VERSION "b"

NS_ :

BS_:

BU_:

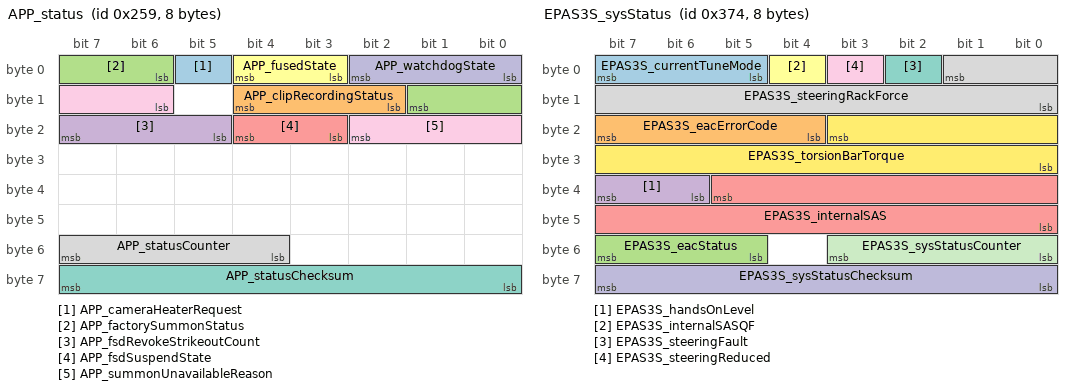
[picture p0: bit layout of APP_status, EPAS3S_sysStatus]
BO_ 601 APP_status: 8 ETH
 SG_ APP_cameraHeaterRequest : 5|1@1+ (1,0) [0|1] "" ETH
 SG_ APP_clipRecordingStatus : 10|3@1+ (1,0) [0|7] "" ETH
 SG_ APP_factorySummonStatus : 6|4@1+ (1,0) [0|15] "" ETH
 SG_ APP_fsdRevokeStrikeoutCount : 21|3@1+ (1,0) [0|7] "" ETH
 SG_ APP_fsdSuspendState : 19|2@1+ (1,0) [0|3] "" ETH
 SG_ APP_fusedState : 3|2@1+ (1,0) [0|3] "" ETH
 SG_ APP_statusChecksum : 56|8@1+ (1,0) [0|255] "" ETH
 SG_ APP_statusCounter : 52|4@1+ (1,0) [0|15] "" ETH
 SG_ APP_summonUnavailableReason : 14|5@1+ (1,0) [0|31] "" ETH
 SG_ APP_watchdogState : 0|3@1+ (1,0) [0|7] "" ETH

BO_ 884 EPAS3S_sysStatus: 8 ETH
 SG_ EPAS3S_currentTuneMode : 5|3@1+ (1,0) [0|7] "" ETH
 SG_ EPAS3S_eacErrorCode : 20|4@1+ (1,0) [0|15] "" ETH
 SG_ EPAS3S_eacStatus : 53|3@1+ (1,0) [0|7] "" ETH
 SG_ EPAS3S_handsOnLevel : 38|2@1+ (1,0) [0|3] "" ETH
 SG_ EPAS3S_internalSAS : 37|14@0+ (0.1,-819.2) [-819.2|819.1] "deg" ETH
 SG_ EPAS3S_internalSASQF : 4|1@1+ (1,0) [0|1] "" ETH
 SG_ EPAS3S_steeringFault : 2|1@1+ (1,0) [0|1] "" ETH
 SG_ EPAS3S_steeringRackForce : 1|10@0+ (50,-25575) [-25575|25575] "N" ETH
 SG_ EPAS3S_steeringReduced : 3|1@1+ (1,0) [0|1] "" ETH
 SG_ EPAS3S_sysStatusChecksum : 56|8@1+ (1,0) [0|255] "" ETH
 SG_ EPAS3S_sysStatusCounter : 48|4@1+ (1,0) [0|15] "" ETH
 SG_ EPAS3S_torsionBarTorque : 19|12@0+ (0.01,-20.5) [-20.5|20.45] "Nm" ETH

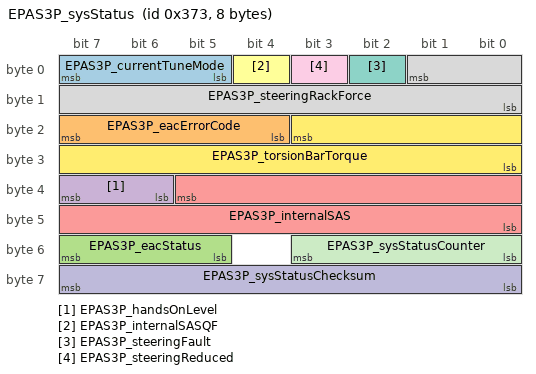
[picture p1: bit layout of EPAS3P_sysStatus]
BO_ 883 EPAS3P_sysStatus: 8 ETH
 SG_ EPAS3P_currentTuneMode : 5|3@1+ (1,0) [0|7] "" ETH
 SG_ EPAS3P_eacErrorCode : 20|4@1+ (1,0) [0|15] "" ETH
 SG_ EPAS3P_eacStatus : 53|3@1+ (1,0) [0|7] "" ETH
 SG_ EPAS3P_handsOnLevel : 38|2@1+ (1,0) [0|3] "" ETH
 SG_ EPAS3P_internalSAS : 37|14@0+ (0.1,-819.2) [-819.2|819.1] "deg" ETH
 SG_ EPAS3P_internalSASQF : 4|1@1+ (1,0) [0|1] "" ETH
 SG_ EPAS3P_steeringFault : 2|1@1+ (1,0) [0|1] "" ETH
 SG_ EPAS3P_steeringRackForce : 1|10@0+ (50,-25575) [-25575|25575] "N" ETH
 SG_ EPAS3P_steeringReduced : 3|1@1+ (1,0) [0|1] "" ETH
 SG_ EPAS3P_sysStatusChecksum : 56|8@1+ (1,0) [0|255] "" ETH
 SG_ EPAS3P_sysStatusCounter : 48|4@1+ (1,0) [0|15] "" ETH
 SG_ EPAS3P_torsionBarTorque : 19|12@0+ (0.01,-20.5) [-20.5|20.45] "Nm" ETH

BO_ 921 DAS_status: 8 ETH
 SG_ DAS_autoLaneChangeState : 46|5@1+ (1,0) [0|31] "" ETH
 SG_ DAS_autoParked : 25|1@1+ (1,0) [0|1] "" ETH
 SG_ DAS_autoparkReady : 24|1@1+ (1,0) [0|1] "" ETH
 SG_ DAS_autoparkWaitingForBrake : 26|1@1+ (1,0) [0|1] "" ETH
 SG_ DAS_autopilotHandsOnState : 42|4@1+ (1,0) [0|15] "" ETH
 SG_ DAS_autopilotState : 0|4@1+ (1,0) [0|15] "" ETH
 SG_ DAS_blindSpotRearLeft : 4|2@1+ (1,0) [0|3] "" ETH
 SG_ DAS_blindSpotRearRight : 6|2@1+ (1,0) [0|3] "" ETH
 SG_ DAS_fleetSpeedState : 40|2@1+ (1,0) [0|3] "" ETH
 SG_ DAS_forwardCollisionWarning : 22|2@1+ (1,0) [0|3] "" ETH
 SG_ DAS_fusedSpeedLimit : 8|5@1+ (5,0) [0|155] "kph/mph" ETH
 SG_ DAS_heaterState : 21|1@1+ (1,0) [0|1] "" ETH
 SG_ DAS_laneDepartureWarning : 37|3@1+ (1,0) [0|7] "" ETH
 SG_ DAS_lssState : 29|3@1+ (1,0) [0|7] "" ETH
 SG_ DAS_sideCollisionAvoid : 32|2@1+ (1,0) [0|3] "" ETH
 SG_ DAS_sideCollisionInhibit : 36|1@1+ (1,0) [0|1] "" ETH
 SG_ DAS_sideCollisionWarning : 34|2@1+ (1,0) [0|3] "" ETH
 SG_ DAS_statusChecksum : 56|8@1+ (1,0) [0|255] "" ETH
 SG_ DAS_statusCounter : 52|4@1+ (1,0) [0|15] "" ETH
 SG_ DAS_summonAvailable : 51|1@1+ (1,0) [0|1] "" ETH
 SG_ DAS_summonClearedGate : 15|1@1+ (1,0) [0|1] "" ETH
 SG_ DAS_summonFwdLeashReached : 27|1@1+ (1,0) [0|1] "" ETH
 SG_ DAS_summonObstacle : 14|1@1+ (1,0) [0|1] "" ETH
 SG_ DAS_summonRvsLeashReached : 28|1@1+ (1,0) [0|1] "" ETH
 SG_ DAS_suppressSpeedWarning : 13|1@1+ (1,0) [0|1] "" ETH
 SG_ DAS_visionOnlySpeedLimit : 16|5@1+ (5,0) [0|155] "kph/mph" ETH

BO_ 1021 UI_autopilotControl: 8 ETH
 SG_ UI_autopilotControlIndex M : 0|3@1+ (1,0) [0|7] "" ETH
 SG_ UI_hovEnabled m0 : 3|1@1+ (1,0) [0|1] "" ETH
 SG_ UI_donDisableAutoWiperDuration m0 : 4|3@1+ (1,0) [0|7] "" ETH
 SG_ UI_donDisableOnAutoWiperSpeed m0 : 7|4@1+ (1,0) [0|15] "" ETH
 SG_ UI_blindspotMinSpeed m0 : 11|4@1+ (1,0) [0|15] "" ETH
 SG_ UI_blindspotDistance m0 : 15|3@1+ (1,0) [0|7] "" ETH
 SG_ UI_blindspotTTC m0 : 18|3@1+ (1,0) [0|7] "" ETH
 SG_ UI_donStopEndOfRampBuffer m0 : 21|3@1+ (1,0) [0|7] "" ETH
 SG_ UI_donDisableCutin m0 : 24|1@1+ (1,0) [0|1] "" ETH
 SG_ UI_smartSetSpeedOffset m0 : 25|6@1+ (1,-30) [-30|33] "%" ETH
 SG_ UI_smartSetSpeedOffsetType m0 : 31|1@1+ (1,0) [0|1] "" ETH
 SG_ UI_fsdVisualizationEnabled m0 : 37|1@1+ (1,0) [0|1] "" ETH
 SG_ UI_fsdStopsControlEnabled m0 : 38|1@1+ (1,0) [0|1] "" ETH
 SG_ UI_fsdContinueOnGreenWithCIPV m0 : 39|1@1+ (1,0) [0|1] "" ETH
 SG_ UI_smartSetSpeed m0 : 40|1@1+ (1,0) [0|1] "" ETH
 SG_ UI_homelinkNearby m0 : 45|1@1+ (1,0) [0|1] "" ETH
 SG_ UI_enableFullSelfDriving m0 : 46|1@1+ (1,0) [0|1] "" ETH
 SG_ UI_hasFullSelfDriving m0 : 47|1@1+ (1,0) [0|1] "" ETH
 SG_ UI_autosteerActivation m0 : 48|1@1+ (1,0) [0|1] "" ETH
 SG_ UI_autopilotDrivingProfile m0 : 49|2@1+ (1,0) [0|3] "" ETH
 SG_ UI_fsdBetaRequest m0 : 51|1@1+ (1,0) [0|1] "" ETH
 SG_ UI_fullSelfDrivingSuspended m0 : 52|1@1+ (1,0) [0|1] "" ETH
 SG_ UI_autopilotControlMux0Valid m0 : 63|1@1+ (1,0) [0|1] "" ETH
 SG_ UI_driverMonitorConfirmation m1 : 17|1@1+ (1,0) [0|1] "" ETH
 SG_ UI_applyEceR79 m1 : 19|1@1+ (1,0) [0|1] "" ETH
 SG_ UI_enableMapStops m1 : 20|1@1+ (1,0) [0|1] "" ETH
 SG_ UI_disableMain m1 : 23|1@1+ (1,0) [0|1] "" ETH
 SG_ UI_disableNarrow m1 : 24|1@1+ (1,0) [0|1] "" ETH
 SG_ UI_disableFisheye m1 : 25|1@1+ (1,0) [0|1] "" ETH
 SG_ UI_disableLeftPillar m1 : 26|1@1+ (1,0) [0|1] "" ETH
 SG_ UI_disableRightPillar m1 : 27|1@1+ (1,0) [0|1] "" ETH
 SG_ UI_disableLeftRepeater m1 : 28|1@1+ (1,0) [0|1] "" ETH
 SG_ UI_disableRightRepeater m1 : 29|1@1+ (1,0) [0|1] "" ETH
 SG_ UI_disableBackup m1 : 30|1@1+ (1,0) [0|1] "" ETH
 SG_ UI_disableRadar m1 : 31|1@1+ (1,0) [0|1] "" ETH
 SG_ UI_noStalkConfirmAlertHaptic m1 : 32|1@1+ (1,0) [0|1] "" ETH
 SG_ UI_ulcSnooze m1 : 36|1@1+ (1,0) [0|1] "" ETH
 SG_ UI_noStalkConfirmAlertChime m1 : 37|1@1+ (1,0) [0|1] "" ETH
 SG_ UI_factorySummonEnable m1 : 39|1@1+ (1,0) [0|1] "" ETH
 SG_ UI_apmv3Branch m1 : 40|3@1+ (1,0) [0|7] "" ETH
 SG_ UI_enableCabinCamera m1 : 43|1@1+ (1,0) [0|1] "" ETH
 SG_ UI_enableAutopilotStopWarning m1 : 44|1@1+ (1,0) [0|1] "" ETH
 SG_ UI_showLaneGraph m1 : 45|1@1+ (1,0) [0|1] "" ETH
 SG_ UI_showTrackLabels m1 : 46|1@1+ (1,0) [0|1] "" ETH
 SG_ UI_hardCoreSummon m1 : 47|1@1+ (1,0) [0|1] "" ETH
 SG_ UI_enableCabinCameraTelemetry m1 : 48|1@1+ (1,0) [0|1] "" ETH
 SG_ UI_enableVisionSpeedControl m1 : 49|1@1+ (1,0) [0|1] "" ETH
 SG_ UI_autopilotTelemetryInChina m1 : 50|1@1+ (1,0) [0|1] "" ETH
 SG_ UI_enableTeslaAutopark m1 : 51|1@1+ (1,0) [0|1] "" ETH
 SG_ UI_autoTurnSignalMode m1 : 52|1@1+ (1,0) [0|1] "" ETH
 SG_ UI_enableCautionLightControl m1 : 54|1@1+ (1,0) [0|1] "" ETH
 SG_ UI_autopilotControlMux1Valid m1 : 63|1@1+ (1,0) [0|1] "" ETH

VAL_ 601 APP_clipRecordingStatus 0 "NO_DRIVE" 1 "IDLE" 2 "RECORDING" 3 "TRIGGERED" 4 "FAULTED" ;
VAL_ 601 APP_factorySummonStatus 0 "SNA" 1 "ACTIVE" 2 "AVAILABLE" 3 "UNAVAILABLE_NO_QR_INSTRUCTION" 4 "UNAVAILABLE_GOAL_TOO_FAR" 5 "UNAVAILABLE_NO_GPS" 6 "UNAVAILABLE_VEHICLE_SPEED_INVALID" 7 "UNAVAILABLE_HEADING_NOT_INITIALIZED" 8 "END_OF_ROUTE" ;
VAL_ 601 APP_fsdRevokeStrikeoutCount 7 "SNA" ;
VAL_ 601 APP_fsdSuspendState 0 "NOT_SUSPENDED" 1 "SUSPENDED" 3 "SNA" ;
VAL_ 601 APP_fusedState 0 "UNKNOWN" 1 "UNFUSED" 2 "FUSED" 3 "SNA" ;
VAL_ 601 APP_summonUnavailableReason 0 "UNKNOWN" 1 "NONE" 2 "NOT_IN_PARK" 3 "CAMERA_STREAM" 4 "CAMERA_BLOCKED" 5 "ULTRASONIC_BLOCKED" 6 "ULTRASONIC_FAULT" 7 "CRUISE_UNAVAILABLE" 8 "EAC_UNAVAILABLE" 9 "PUBLIC_ROAD" 10 "POOR_CONNECTION" 11 "PHONE_GPS_UNAVAILABLE" 12 "EGO_GPS_UNAVAILABLE" 13 "PHONE_IS_TOO_FAR" 14 "END_OF_LEASH" 15 "CAMERA_NOT_CALIBRATED" 16 "VISION_HEALTH_CRITICAL" 17 "ULTRASONIC_STALE" 18 "ALL_SENSORS_OCCLUDED" 19 "PUBLIC_ROAD_BOUNDARIES_NOT_VALID" 20 "NO_CONTEXT" ;
VAL_ 601 APP_watchdogState 0 "UNKNOWN" 1 "DEGRADED" 2 "CRITICAL" 3 "HEALTHY" 7 "SNA" ;
VAL_ 884 EPAS3S_currentTuneMode 0 "DM_COMFORT" 1 "DM_STANDARD" 2 "DM_SPORT" 3 "RWD_COMFORT" 4 "RWD_STANDARD" 5 "RWD_SPORT" ;
VAL_ 884 EPAS3S_eacErrorCode 0 "EAC_ERROR_IDLE" 1 "EAC_ERROR_MIN_SPEED" 2 "EAC_ERROR_MAX_SPEED" 3 "EAC_ERROR_HANDS_ON" 4 "EAC_ERROR_TMP_FAULT" 5 "EAR_ERROR_MAX_STEER_DELTA" 6 "EAC_ERROR_HIGH_ANGLE_REQ" 7 "EAC_ERROR_HIGH_ANGLE_RATE_REQ" 8 "EAC_ERROR_HIGH_ANGLE_SAFETY" 9 "EAC_ERROR_HIGH_ANGLE_RATE_SAFETY" 10 "EAC_ERROR_HIGH_MMOT_SAFETY" 11 "EAC_ERROR_HIGH_TORSION_SAFETY" 12 "EAC_ERROR_LOW_ASSIST" 13 "EAC_ERROR_PINION_VEL_DIFF" 14 "EAC_EXTERNAL_MONITOR_INHIBIT" 15 "SNA" ;
VAL_ 884 EPAS3S_eacStatus 0 "INHIBITED" 1 "AVAILABLE" 2 "ACTIVE" 3 "FAULT" 4 "LKA_ELK_AVAILABLE" 5 "LKA_ACTIVE" 6 "ELK_AVAILABLE" 7 "ELK_ACTIVE" ;
VAL_ 884 EPAS3S_handsOnLevel 0 "0" 1 "1" 2 "2" 3 "3" ;
VAL_ 884 EPAS3S_internalSASQF 0 "UNDEFINABLE_ACCURACY" 1 "IN_SPEC" ;
VAL_ 884 EPAS3S_steeringFault 0 "NO_FAULT" 1 "FAULT" ;
VAL_ 884 EPAS3S_steeringRackForce 1022 "NOT_IN_SPEC" 1023 "SNA" ;
VAL_ 884 EPAS3S_steeringReduced 0 "NORMAL_ASSIST" 1 "REDUCED_ASSIST" ;
VAL_ 884 EPAS3S_torsionBarTorque 4094 "UNDEFINABLE_DATA" 4095 "SNA" ;
VAL_ 883 EPAS3P_handsOnLevel 0 "0" 1 "1" 2 "2" 3 "3" ;
VAL_ 921 DAS_autoLaneChangeState 0 "UNAVAILABLE_DISABLED" 1 "UNAVAILABLE_NO_LANES" 2 "UNAVAILABLE_SONICS_INVALID" 3 "UNAVAILABLE_TP_FOLLOW" 4 "UNAVAILABLE_EXITING_HIGHWAY" 5 "UNAVAILABLE_VEHICLE_SPEED" 6 "AVAILABLE_ONLY_L" 7 "AVAILABLE_ONLY_R" 8 "AVAILABLE_BOTH" 9 "IN_PROGRESS_L" 10 "IN_PROGRESS_R" 11 "WAITING_FOR_SIDE_OBST_TO_PASS_L" 12 "WAITING_FOR_SIDE_OBST_TO_PASS_R" 13 "WAITING_FOR_FWD_OBST_TO_PASS_L" 14 "WAITING_FOR_FWD_OBST_TO_PASS_R" 15 "ABORT_SIDE_OBSTACLE_PRESENT_L" 16 "ABORT_SIDE_OBSTACLE_PRESENT_R" 17 "ABORT_POOR_VIEW_RANGE" 18 "ABORT_LC_HEALTH_BAD" 19 "ABORT_BLINKER_TURNED_OFF" 20 "ABORT_OTHER_REASON" 21 "UNAVAILABLE_SOLID_LANE_LINE" 22 "BLOCKED_VEH_TTC_L" 23 "BLOCKED_VEH_TTC_AND_USS_L" 24 "BLOCKED_VEH_TTC_R" 25 "BLOCKED_VEH_TTC_AND_USS_R" 26 "BLOCKED_LANE_TYPE_L" 27 "BLOCKED_LANE_TYPE_R" 28 "WAITING_HANDS_ON" 29 "ABORT_TIMEOUT" 30 "ABORT_MISSION_PLAN_INVALID" 31 "SNA" ;
VAL_ 921 DAS_autoparkReady 0 "UNAVAILABLE" 1 "READY" ;
VAL_ 921 DAS_autopilotHandsOnState 0 "NOT_REQD" 1 "REQD_DETECTED" 2 "REQD_NOT_DETECTED" 3 "REQD_VISUAL" 4 "REQD_CHIME_1" 5 "REQD_CHIME_2" 6 "REQD_SLOWING" 7 "REQD_STRUCK_OUT" 8 "SUSPENDED" 9 "REQD_ESCALATED_CHIME_1" 10 "REQD_ESCALATED_CHIME_2" 15 "SNA" ;
VAL_ 921 DAS_autopilotState 0 "DISABLED" 1 "UNAVAILABLE" 2 "AVAILABLE" 3 "ACTIVE_NOMINAL" 4 "ACTIVE_RESTRICTED" 5 "ACTIVE_NAV" 6 "ACTIVE_FSD" 8 "ABORTING" 9 "ABORTED" 14 "FAULT" 15 "SNA" ;
VAL_ 921 DAS_blindSpotRearLeft 0 "NO_WARNING" 1 "WARNING_LEVEL_1" 2 "WARNING_LEVEL_2" 3 "SNA" ;
VAL_ 921 DAS_blindSpotRearRight 0 "NO_WARNING" 1 "WARNING_LEVEL_1" 2 "WARNING_LEVEL_2" 3 "SNA" ;
VAL_ 921 DAS_fleetSpeedState 0 "UNAVAILABLE" 1 "AVAILABLE" 2 "ACTIVE" 3 "HOLD" ;
VAL_ 921 DAS_forwardCollisionWarning 0 "NONE" 1 "FORWARD_COLLISION_WARNING" 3 "SNA" ;
VAL_ 921 DAS_fusedSpeedLimit 0 "UNKNOWN_SNA" 31 "NONE" ;
VAL_ 921 DAS_heaterState 0 "OFF_SNA" 1 "ON" ;
VAL_ 921 DAS_laneDepartureWarning 0 "NONE" 1 "LEFT_WARNING" 2 "RIGHT_WARNING" 3 "LEFT_WARNING_SEVERE" 4 "RIGHT_WARNING_SEVERE" 5 "SNA" ;
VAL_ 921 DAS_lssState 0 "FAULT" 1 "LDW" 2 "LKA" 3 "ELK" 4 "MONITOR" 5 "BLINDSPOT" 6 "ABORT" 7 "OFF" ;
VAL_ 921 DAS_sideCollisionAvoid 0 "NONE" 1 "AVOID_LEFT" 2 "AVOID_RIGHT" 3 "SNA" ;
VAL_ 921 DAS_sideCollisionInhibit 0 "NO_INHIBIT" 1 "INHIBIT" ;
VAL_ 921 DAS_sideCollisionWarning 0 "NONE" 1 "WARN_LEFT" 2 "WARN_RIGHT" 3 "WARN_LEFT_RIGHT" ;
VAL_ 921 DAS_suppressSpeedWarning 0 "Do_Not_Suppress" 1 "Suppress_Speed_Warning" ;
VAL_ 921 DAS_visionOnlySpeedLimit 0 "UNKNOWN_SNA" 31 "NONE" ;
VAL_ 1021 UI_autopilotControlIndex 0 "0" 1 "1" 2 "2" 3 "3" 4 "4" 5 "5" 6 "6" 7 "7" ;
VAL_ 1021 UI_hovEnabled 0 "OFF" 1 "ON" ;
VAL_ 1021 UI_donDisableAutoWiperDuration 0 "DEFAULT" 1 "5_S" 2 "15_S" 3 "30_S" 4 "60_S" 5 "120_S" 6 "OFF" ;
VAL_ 1021 UI_donDisableOnAutoWiperSpeed 0 "OFF" 1 "1" 2 "2" 3 "3" 4 "4" 5 "5" 6 "6" 7 "7" 8 "8" 9 "9" 10 "10" 11 "11" 12 "12" 13 "13" 14 "14" 15 "INVALID" ;
VAL_ 1021 UI_blindspotMinSpeed 0 "DEFAULT" 1 "5_KPH" 2 "10_KPH" 3 "15_KPH" 4 "20_KPH" 5 "25_KPH" 6 "30_KPH" 7 "35_KPH" 8 "40_KPH" 9 "45_KPH" 10 "OFF" ;
VAL_ 1021 UI_blindspotDistance 0 "DEFAULT" 1 "0P5_M" 2 "1_M" 3 "2_M" 4 "4_M" 5 "OFF" ;
VAL_ 1021 UI_blindspotTTC 0 "DEFAULT" 1 "0P5_S" 2 "1_S" 3 "2_S" 4 "4_S" 5 "3_S" 6 "5_S" 7 "OFF" ;
VAL_ 1021 UI_donStopEndOfRampBuffer 0 "DEFAULT" 1 "15_M" 2 "30_M" 3 "45_M" 4 "OFF" ;
VAL_ 1021 UI_donDisableCutin 0 "OFF" 1 "ON" ;
VAL_ 1021 UI_smartSetSpeedOffsetType 0 "FIXED_OFFSET" 1 "PERCENTAGE_OFFSET" ;
VAL_ 1021 UI_homelinkNearby 0 "NOT_NEARBY" 1 "NEARBY" ;
VAL_ 1021 UI_autosteerActivation 0 "SINGLE_CLICK" 1 "DOUBLE_CLICK" ;
VAL_ 1021 UI_autopilotDrivingProfile 0 "CHILL" 1 "NORMAL" 2 "ASSERTIVE" ;
VAL_ 1021 UI_fsdBetaRequest 0 "NOT_ACTIVE" 1 "ACTIVE" ;
VAL_ 1021 UI_apmv3Branch 0 "LIVE" 1 "STAGE" 2 "DEV" 3 "STAGE2" 4 "EAP" 5 "DEMO" ;
VAL_ 1021 UI_autoTurnSignalMode 0 "OFF" 1 "AUTO_CANCEL" ;
